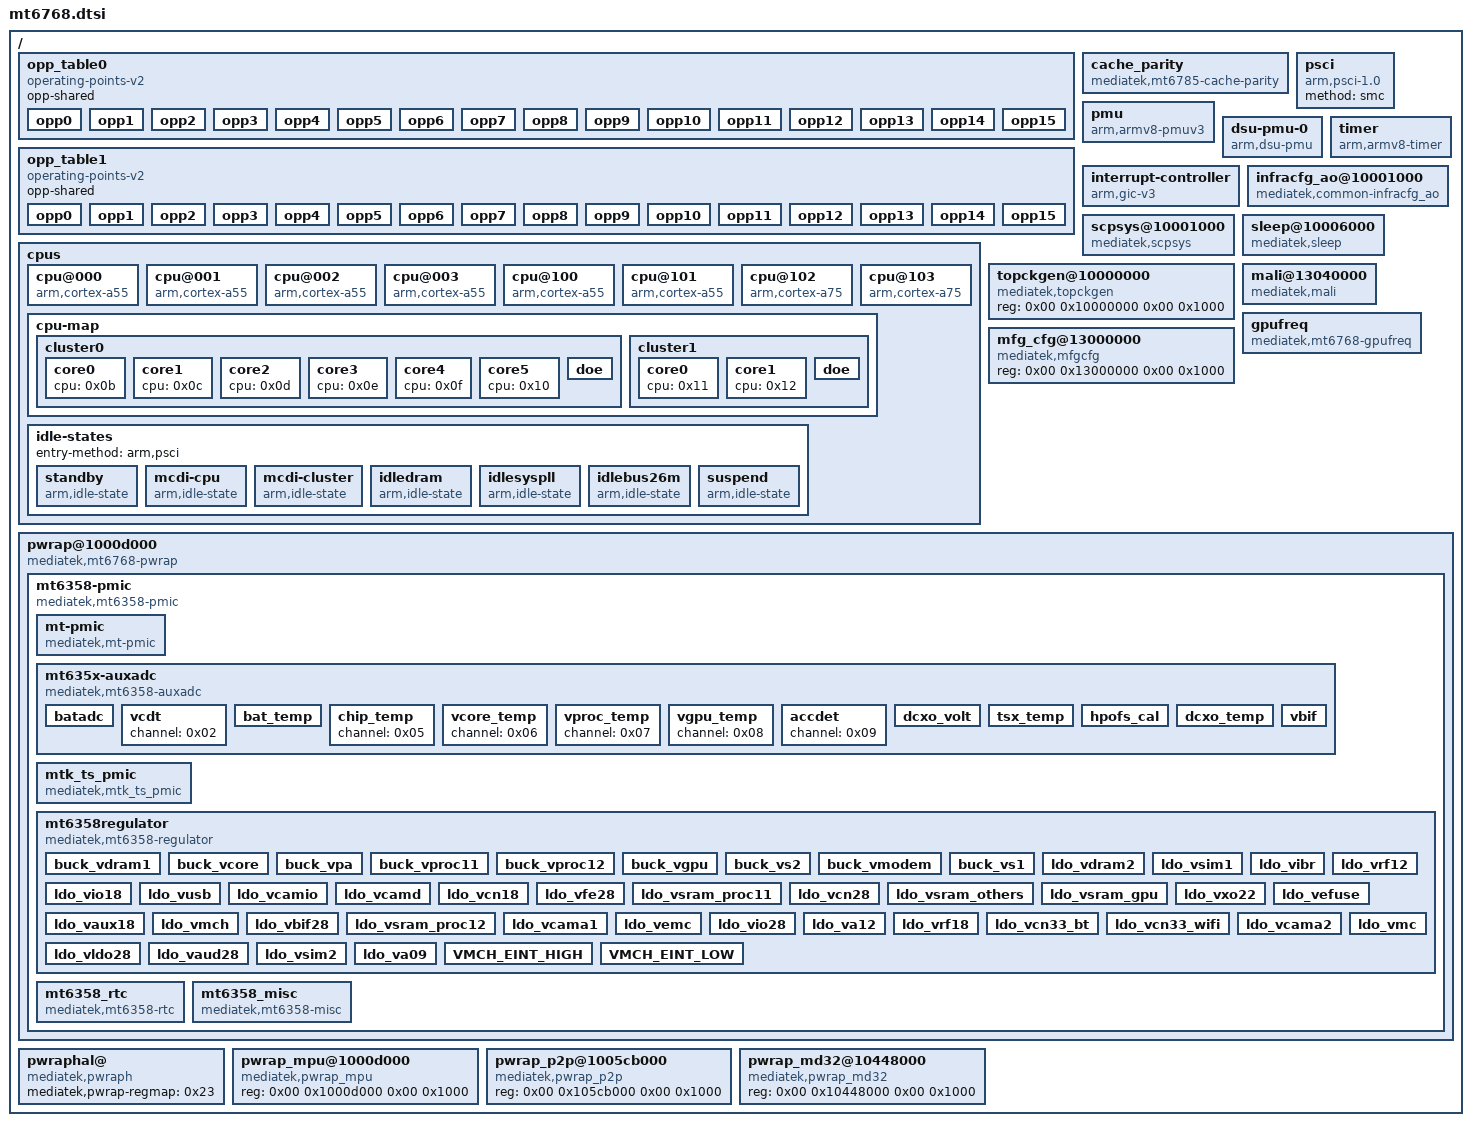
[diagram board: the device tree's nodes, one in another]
// SPDX-License-Identifier: GPL-2.0-only
// Shared MediaTek MT6768/MT6769Z resources.
/ {

	opp_table0 {
		compatible = "operating-points-v2";
		opp-shared;
		phandle = <0x02>;

		opp0 {
			opp-hz = <0x00 0x1dcd6500>;
			opp-microvolt = <0x9eb10>;
		};

		opp1 {
			opp-hz = <0x00 0x2e224d80>;
			opp-microvolt = <0xa4cb8>;
		};

		opp2 {
			opp-hz = <0x00 0x32a9f880>;
			opp-microvolt = <0xaae60>;
		};

		opp3 {
			opp-hz = <0x00 0x35a4e900>;
			opp-microvolt = <0xaf79e>;
		};

		opp4 {
			opp-hz = <0x00 0x389fd980>;
			opp-microvolt = <0xb2872>;
		};

		opp5 {
			opp-hz = <0x00 0x3b8b87c0>;
			opp-microvolt = <0xb5946>;
		};

		opp6 {
			opp-hz = <0x00 0x3e95ba80>;
			opp-microvolt = <0xba284>;
		};

		opp7 {
			opp-hz = <0x00 0x4190ab00>;
			opp-microvolt = <0xbd358>;
		};

		opp8 {
			opp-hz = <0x00 0x460913c0>;
			opp-microvolt = "\0\f5";
		};

		opp9 {
			opp-hz = <0x00 0x4bfef4c0>;
			opp-microvolt = <0xcaf12>;
		};

		opp10 {
			opp-hz = <0x00 0x4ef9e540>;
			opp-microvolt = <0xcdfe6>;
		};

		opp11 {
			opp-hz = <0x00 0x51f4d5c0>;
			opp-microvolt = <0xd10ba>;
		};

		opp12 {
			opp-hz = <0x00 0x566d3e80>;
			opp-microvolt = <0xd7262>;
		};

		opp13 {
			opp-hz = <0x00 0x59682f00>;
			opp-microvolt = <0xda336>;
		};

		opp14 {
			opp-hz = <0x00 0x60db8840>;
			opp-microvolt = <0xe35b2>;
		};

		opp15 {
			opp-hz = <0x00 0x6553f100>;
			opp-microvolt = <0xeafc4>;
		};
	};

	opp_table1 {
		compatible = "operating-points-v2";
		opp-shared;
		phandle = <0x0a>;

		opp0 {
			opp-hz = <0x00 0x32a9f880>;
			opp-microvolt = <0xa4cb8>;
		};

		opp1 {
			opp-hz = <0x00 0x362e3d40>;
			opp-microvolt = <0xaae60>;
		};

		opp2 {
			opp-hz = <0x00 0x3b7c4580>;
			opp-microvolt = <0xb2872>;
		};

		opp3 {
			opp-hz = <0x00 0x40ca4dc0>;
			opp-microvolt = <0xbbaee>;
		};

		opp4 {
			opp-hz = <0x00 0x46185600>;
			opp-microvolt = "\0\f5";
		};

		opp5 {
			opp-hz = <0x00 0x4d3021c0>;
			opp-microvolt = <0xcdfe6>;
		};

		opp6 {
			opp-hz = <0x00 0x50b46680>;
			opp-microvolt = <0xd418e>;
		};

		opp7 {
			opp-hz = <0x00 0x56026ec0>;
			opp-microvolt = <0xdbba0>;
		};

		opp8 {
			opp-hz = <0x00 0x5b507700>;
			opp-microvolt = <0xe35b2>;
		};

		opp9 {
			opp-hz = <0x00 0x609e7f40>;
			opp-microvolt = <0xec82e>;
		};

		opp10 {
			opp-hz = <0x00 0x65ec8780>;
			opp-microvolt = <0xf4240>;
		};

		opp11 {
			opp-hz = <0x00 0x6b49d200>;
			opp-microvolt = <0xfbc52>;
		};

		opp12 {
			opp-hz = <0x00 0x6e44c280>;
			opp-microvolt = <0x100590>;
		};

		opp13 {
			opp-hz = <0x00 0x713fb300>;
			opp-microvolt = <0x103664>;
		};

		opp14 {
			opp-hz = <0x00 0x743aa380>;
			opp-microvolt = <0x106738>;
		};

		opp15 {
			opp-hz = <0x00 0x77359400>;
			opp-microvolt = <0x10980c>;
		};
	};

	cpus {
		#address-cells = <0x01>;
		#size-cells = <0x00>;

		cpu@000 {
			device_type = "cpu";
			compatible = "arm,cortex-a55";
			reg = <0x00>;
			enable-method = "psci";
			clock-frequency = <0x65633340>;
			operating-points-v2 = <0x02>;
			dynamic-power-coefficient = <0x55>;
			capacity-dmips-mhz = <0x1ef>;
			cpu-idle-states = <0x03 0x04 0x05 0x06 0x07 0x08 0x09>;
			phandle = <0x0b>;
		};

		cpu@001 {
			device_type = "cpu";
			compatible = "arm,cortex-a55";
			reg = <0x100>;
			enable-method = "psci";
			clock-frequency = <0x65633340>;
			operating-points-v2 = <0x02>;
			dynamic-power-coefficient = <0x55>;
			capacity-dmips-mhz = <0x1ef>;
			cpu-idle-states = <0x03 0x04 0x05 0x06 0x07 0x08 0x09>;
			phandle = <0x0c>;
		};

		cpu@002 {
			device_type = "cpu";
			compatible = "arm,cortex-a55";
			reg = <0x200>;
			enable-method = "psci";
			clock-frequency = <0x65633340>;
			operating-points-v2 = <0x02>;
			dynamic-power-coefficient = <0x55>;
			capacity-dmips-mhz = <0x1ef>;
			cpu-idle-states = <0x03 0x04 0x05 0x06 0x07 0x08 0x09>;
			phandle = <0x0d>;
		};

		cpu@003 {
			device_type = "cpu";
			compatible = "arm,cortex-a55";
			reg = <0x300>;
			enable-method = "psci";
			clock-frequency = <0x65633340>;
			operating-points-v2 = <0x02>;
			dynamic-power-coefficient = <0x55>;
			capacity-dmips-mhz = <0x1ef>;
			cpu-idle-states = <0x03 0x04 0x05 0x06 0x07 0x08 0x09>;
			phandle = <0x0e>;
		};

		cpu@100 {
			device_type = "cpu";
			compatible = "arm,cortex-a55";
			reg = <0x400>;
			enable-method = "psci";
			clock-frequency = <0x65633340>;
			operating-points-v2 = <0x02>;
			dynamic-power-coefficient = <0x55>;
			capacity-dmips-mhz = <0x1ef>;
			cpu-idle-states = <0x03 0x04 0x05 0x06 0x07 0x08 0x09>;
			phandle = <0x0f>;
		};

		cpu@101 {
			device_type = "cpu";
			compatible = "arm,cortex-a55";
			reg = <0x500>;
			enable-method = "psci";
			clock-frequency = <0x65633340>;
			operating-points-v2 = <0x02>;
			dynamic-power-coefficient = <0x55>;
			capacity-dmips-mhz = <0x1ef>;
			cpu-idle-states = <0x03 0x04 0x05 0x06 0x07 0x08 0x09>;
			phandle = <0x10>;
		};

		cpu@102 {
			device_type = "cpu";
			compatible = "arm,cortex-a75";
			reg = <0x600>;
			enable-method = "psci";
			clock-frequency = <0x8166d4c0>;
			operating-points-v2 = <0x0a>;
			dynamic-power-coefficient = <0x113>;
			capacity-dmips-mhz = <0x400>;
			cpu-idle-states = <0x03 0x04 0x05 0x06 0x07 0x08 0x09>;
			phandle = <0x11>;
		};

		cpu@103 {
			device_type = "cpu";
			compatible = "arm,cortex-a75";
			reg = <0x700>;
			enable-method = "psci";
			clock-frequency = <0x8166d4c0>;
			operating-points-v2 = <0x0a>;
			dynamic-power-coefficient = <0x113>;
			capacity-dmips-mhz = <0x400>;
			cpu-idle-states = <0x03 0x04 0x05 0x06 0x07 0x08 0x09>;
			phandle = <0x12>;
		};

		cpu-map {

			cluster0 {

				core0 {
					cpu = <0x0b>;
				};

				core1 {
					cpu = <0x0c>;
				};

				core2 {
					cpu = <0x0d>;
				};

				core3 {
					cpu = <0x0e>;
				};

				core4 {
					cpu = <0x0f>;
				};

				core5 {
					cpu = <0x10>;
				};

				doe {
					phandle = <0x74>;
				};
			};

			cluster1 {

				core0 {
					cpu = <0x11>;
				};

				core1 {
					cpu = <0x12>;
				};

				doe {
					phandle = <0x75>;
				};
			};
		};

		idle-states {
			entry-method = "arm,psci";

			standby {
				compatible = "arm,idle-state";
				arm,psci-suspend-param = <0x01>;
				entry-latency-us = <0x258>;
				exit-latency-us = <0x258>;
				min-residency-us = <0x4b0>;
				phandle = <0x03>;
			};

			mcdi-cpu {
				compatible = "arm,idle-state";
				arm,psci-suspend-param = <0x10001>;
				entry-latency-us = <0x258>;
				exit-latency-us = <0x258>;
				min-residency-us = <0x4b0>;
				phandle = <0x04>;
			};

			mcdi-cluster {
				compatible = "arm,idle-state";
				arm,psci-suspend-param = <0x1010001>;
				entry-latency-us = <0x258>;
				exit-latency-us = <0x258>;
				min-residency-us = <0x4b0>;
				phandle = <0x05>;
			};

			idledram {
				compatible = "arm,idle-state";
				arm,psci-suspend-param = <0x1010002>;
				entry-latency-us = <0x320>;
				exit-latency-us = <0x3e8>;
				min-residency-us = <0x7d0>;
				status = "okay";
				phandle = <0x06>;
			};

			idlesyspll {
				compatible = "arm,idle-state";
				arm,psci-suspend-param = <0x1010003>;
				entry-latency-us = <0x320>;
				exit-latency-us = <0x3e8>;
				min-residency-us = <0x7d0>;
				status = "okay";
				phandle = <0x07>;
			};

			idlebus26m {
				compatible = "arm,idle-state";
				arm,psci-suspend-param = <0x1010004>;
				entry-latency-us = <0x320>;
				exit-latency-us = <0x3e8>;
				min-residency-us = <0x7d0>;
				status = "okay";
				phandle = <0x08>;
			};

			suspend {
				compatible = "arm,idle-state";
				arm,psci-suspend-param = <0x1010005>;
				entry-latency-us = <0x320>;
				exit-latency-us = <0x3e8>;
				min-residency-us = <0x7d0>;
				phandle = <0x09>;
			};
		};
	};

	cache_parity {
		compatible = "mediatek,mt6785-cache-parity";
		reg = <0x00 0xc530000 0x00 0x10000>;
		irq_config = <0x00 0x8090 0xff00 0x8090 0x44 0x8090 0xff 0x01 0x8090 0xff00 0x8090 0x44 0x8090 0xff 0x02 0x8090 0xff00 0x8090 0x44 0x8090 0xff 0x03 0x8090 0xff00 0x8090 0x44 0x8090 0xff 0x04 0x8090 0xff00 0x8090 0x44 0x8090 0xff 0x05 0x8090 0xff00 0x8090 0x44 0x8090 0xff 0x06 0x8090 0xff00 0x8090 0x44 0x8090 0xff 0x07 0x8090 0xff00 0x8090 0x44 0x8090 0xff 0x400 0xc8c0 0x1000000 0xc8c0 0x0c 0xc8c8 0x01>;
		interrupts = <0x00 0x16 0x04 0x00 0x17 0x04 0x00 0x18 0x04 0x00 0x19 0x04 0x00 0x1a 0x04 0x00 0x1b 0x04 0x00 0x1c 0x04 0x00 0x1d 0x04 0x00 0x13 0x04>;
	};

	psci {
		compatible = "arm,psci-1.0";
		method = "smc";
	};

	pmu {
		compatible = "arm,armv8-pmuv3";
		interrupt-parent = <0x13>;
		interrupts = <0x01 0x07 0x08>;
	};

	dsu-pmu-0 {
		compatible = "arm,dsu-pmu";
		interrupts = <0x00 0x12 0x04>;
		cpus = <0x0b 0x0c 0x0d 0x0e 0x0f 0x10 0x11 0x12>;
	};

	interrupt-controller {
		compatible = "arm,gic-v3";
		#interrupt-cells = <0x03>;
		#address-cells = <0x02>;
		#size-cells = <0x02>;
		#redistributor-regions = <0x01>;
		interrupt-parent = <0x13>;
		interrupt-controller;
		reg = <0x00 0xc000000 0x00 0x40000 0x00 0xc040000 0x00 0x200000 0x00 0xc53a650 0x00 0x50>;
		interrupts = <0x01 0x09 0x04>;
		phandle = <0x13>;
	};

	timer {
		compatible = "arm,armv8-timer";
		interrupt-parent = <0x13>;
		interrupts = <0x01 0x0d 0x08 0x01 0x0e 0x08 0x01 0x0b 0x08 0x01 0x0a 0x08>;
		clock-frequency = <0xc65d40>;
		phandle = <0x78>;
	};

	infracfg_ao@10001000 {
		compatible = "mediatek,common-infracfg_ao\0mediatek,infracfg_ao\0syscon";
		reg = <0x00 0x10001000 0x00 0x1000>;
		interrupts = <0x00 0x47 0x01>;
		#clock-cells = <0x01>;
		phandle = <0x26>;
	};

	scpsys@10001000 {
		compatible = "mediatek,scpsys\0syscon";
		reg = <0x00 0x10001000 0x00 0x1000 0x00 0x10006000 0x00 0x1000 0x00 0x14002000 0x00 0x1000 0x00 0x1020e000 0x00 0x1000 0x00 0x18004000 0x00 0x1000 0x00 0x18002000 0x00 0x1000 0x00 0x10000000 0x00 0x1000 0x00 0x16000000 0x00 0x1000 0x00 0x16025000 0x00 0x1000>;
		#clock-cells = <0x01>;
		phandle = <0x27>;
	};

	topckgen@10000000 {
		compatible = "mediatek,topckgen\0syscon";
		reg = <0x00 0x10000000 0x00 0x1000>;
		#clock-cells = <0x01>;
		phandle = <0x14>;
	};

	sleep@10006000 {
		spmfw_version = "pcm_allinone_lp4_term_3200_v1p11\0pcm_allinone_lp4_3600_v1p11\0pcm_allinone_lp4_3200_v1p11\0pcm_allinone_lp3_1866_v1p11";
		compatible = "mediatek,sleep";
		reg = <0x00 0x10006000 0x00 0x1000>;
		interrupts = <0x00 0xc3 0x08>;
		phandle = <0x7d>;
	};

	mfg_cfg@13000000 {
		compatible = "mediatek,mfgcfg\0syscon";
		reg = <0x00 0x13000000 0x00 0x1000>;
		#clock-cells = <0x01>;
		phandle = <0x60>;
	};

	mali@13040000 {
		compatible = "mediatek,mali\0arm,mali-valhall";
		reg = <0x00 0x13040000 0x00 0x4000>;
		interrupts = <0x00 0x112 0x08 0x00 0x113 0x08 0x00 0x114 0x08 0x00 0x115 0x08 0x00 0x116 0x08>;
		interrupt-names = "GPU\0MMU\0JOB\0EVENT\0PWR";
		ged-supply = <0x5f>;
	};

	gpufreq {
		compatible = "mediatek,mt6768-gpufreq";
		clocks = <0x14 0x54 0x14 0x26 0x14 0x06 0x60 0x00 0x27 0x09 0x27 0x04 0x27 0x07 0x27 0x08>;
		clock-names = "clk_mux\0clk_main_parent\0clk_sub_parent\0subsys_mfg_cg\0mtcmos_mfg_async\0mtcmos_mfg\0mtcmos_mfg_core0\0mtcmos_mfg_core1";
		nvmem-cells = <0x61>;
		nvmem-cell-names = "efuse_segment_cell";
		phandle = <0x62>;
	};

	pwrap@1000d000 {
		compatible = "mediatek,mt6768-pwrap";
		reg = <0x00 0x1000d000 0x00 0x1000>;
		reg-names = "pwrap";
		interrupts = <0x00 0xc2 0x04>;
		clocks = <0x15 0x15>;
		clock-names = "spi\0wrap";
		phandle = <0x23>;

		mt6358-pmic {
			compatible = "mediatek,mt6358-pmic";
			interrupt-parent = <0x20>;
			interrupts = <0x90 0x04 0xb4 0x00>;
			status = "okay";
			interrupt-controller;
			#interrupt-cells = <0x02>;
			mediatek,num-pmic-irqs = <0x91>;
			mediatek,pmic-irqs = <0x00 0x00 0x01 0x00 0x02 0x00 0x03 0x00 0x04 0x00 0x05 0x00 0x06 0x00 0x07 0x00 0x08 0x00 0x09 0x00 0x10 0x01 0x11 0x01 0x12 0x01 0x13 0x01 0x14 0x01 0x15 0x01 0x16 0x01 0x17 0x01 0x18 0x01 0x19 0x01 0x1a 0x01 0x1b 0x01 0x1c 0x01 0x1d 0x01 0x1e 0x01 0x1f 0x01 0x20 0x01 0x21 0x01 0x22 0x01 0x23 0x01 0x24 0x01 0x25 0x01 0x26 0x01 0x27 0x01 0x28 0x01 0x29 0x01 0x2a 0x01 0x2b 0x01 0x2c 0x01 0x2d 0x01 0x2e 0x01 0x30 0x02 0x31 0x02 0x32 0x02 0x33 0x02 0x34 0x02 0x35 0x02 0x36 0x02 0x37 0x02 0x40 0x03 0x50 0x04 0x51 0x04 0x52 0x04 0x53 0x04 0x54 0x04 0x55 0x04 0x56 0x04 0x57 0x04 0x58 0x04 0x59 0x04 0x5a 0x04 0x5b 0x04 0x5c 0x04 0x60 0x04 0x61 0x04 0x62 0x04 0x63 0x04 0x64 0x04 0x70 0x05 0x71 0x05 0x72 0x05 0x73 0x05 0x74 0x05 0x75 0x05 0x76 0x05 0x77 0x05 0x80 0x06 0x85 0x06 0x86 0x06 0x87 0x06 0x90 0x07>;
			interrupt-names = "vproc11_oc\0vproc12_oc\0vcore_oc\0vgpu_oc\0vmodem_oc\0vdram1_oc\0vs1_oc\0vs2_oc\0vpa_oc\0vcore_preoc\0vfe28_oc\0vxo22_oc\0vrf18_oc\0vrf12_oc\0vefuse_oc\0vcn33_oc\0vcn28_oc\0vcn18_oc\0vcama1_oc\0vcama2_oc\0vcamd_oc\0vcamio_oc\0vldo28_oc\0va12_oc\0vaux18_oc\0vaud28_oc\0vio28_oc\0vio18_oc\0vsram_proc11_oc\0vsram_proc12_oc\0vsram_others_oc\0vsram_gpu_oc\0vdram2_oc\0vmc_oc\0vmch_oc\0vemc_oc\0vsim1_oc\0vsim2_oc\0vibr_oc\0vusb_oc\0vbif28_oc\0pwrkey\0homekey\0pwrkey_r\0homekey_r\0ni_lbat_int\0chrdet\0chrdet_edge\0vcdt_hv_det\0rtc\0fg_bat0_h\0fg_bat0_l\0fg_cur_h\0fg_cur_l\0fg_zcv\0fg_bat1_h\0fg_bat1_l\0fg_n_charge_l\0fg_iavg_h\0fg_iavg_l\0fg_time_h\0fg_discharge\0fg_charge\0baton_lv\0baton_ht\0baton_bat_in\0baton_bat_out\0bif\0bat_h\0bat_l\0bat2_h\0bat2_l\0bat_temp_h\0bat_temp_l\0auxadc_imp\0nag_c_dltv\0audio\0accdet\0accdet_eint0\0accdet_eint1\0spi_cmd_alert";
			phandle = <0x81>;

			mt-pmic {
				compatible = "mediatek,mt-pmic";
				interrupts = <0x30 0x04 0x32 0x04 0x31 0x04 0x33 0x04 0x70 0x04 0x71 0x04 0x52 0x04 0x53 0x04 0x36 0x03>;
				interrupt-names = "pwrkey\0pwrkey_r\0homekey\0homekey_r\0bat_h\0bat_l\0fg_cur_h\0fg_cur_l\0chrdet_edge";
				phandle = <0x82>;
			};

			mt635x-auxadc {
				compatible = "mediatek,mt6358-auxadc";
				#io-channel-cells = <0x01>;
				phandle = <0x21>;

				batadc {
					channel = <0x00>;
					resistance-ratio = <0x03 0x01>;
					avg-num = <0x80>;
				};

				vcdt {
					channel = <0x02>;
				};

				bat_temp {
					channel = <0x03>;
					resistance-ratio = <0x02 0x01>;
				};

				chip_temp {
					channel = <0x05>;
				};

				vcore_temp {
					channel = <0x06>;
				};

				vproc_temp {
					channel = <0x07>;
				};

				vgpu_temp {
					channel = <0x08>;
				};

				accdet {
					channel = <0x09>;
				};

				dcxo_volt {
					channel = <0x0a>;
					resistance-ratio = <0x03 0x02>;
				};

				tsx_temp {
					channel = <0x0b>;
					avg-num = <0x80>;
				};

				hpofs_cal {
					channel = <0x0c>;
					avg-num = <0x100>;
				};

				dcxo_temp {
					channel = <0x0d>;
					avg-num = <0x10>;
				};

				vbif {
					channel = <0x0e>;
					resistance-ratio = <0x02 0x01>;
				};
			};

			mtk_ts_pmic {
				compatible = "mediatek,mtk_ts_pmic";
				io-channels = <0x21 0x05 0x21 0x06 0x21 0x07>;
				io-channel-names = "pmic_chip_temp\0pmic_buck1_temp\0pmic_buck2_temp";
				interconnects = <0x21 0x01>;
				#interconnect-cells = <0x01>;
				phandle = <0x83>;
			};

			mt6358regulator {
				compatible = "mediatek,mt6358-regulator";
				phandle = <0x84>;

				buck_vdram1 {
					regulator-name = "vdram1";
					regulator-min-microvolt = <0x7a120>;
					regulator-max-microvolt = <0x1fda4c>;
					regulator-enable-ramp-delay = <0x00>;
					phandle = <0x85>;
				};

				buck_vcore {
					regulator-name = "vcore";
					regulator-min-microvolt = <0x7a120>;
					regulator-max-microvolt = <0x13bdb6>;
					regulator-enable-ramp-delay = <0xc8>;
					phandle = <0x29>;
				};

				buck_vpa {
					regulator-name = "vpa";
					regulator-min-microvolt = <0x7a120>;
					regulator-max-microvolt = <0x37b1d0>;
					regulator-enable-ramp-delay = <0xfa>;
					phandle = <0x86>;
				};

				buck_vproc11 {
					regulator-name = "vproc11";
					regulator-min-microvolt = <0x7a120>;
					regulator-max-microvolt = <0x13bdb6>;
					regulator-enable-ramp-delay = <0xc8>;
					phandle = <0x87>;
				};

				buck_vproc12 {
					regulator-name = "vproc12";
					regulator-min-microvolt = <0x7a120>;
					regulator-max-microvolt = <0x13bdb6>;
					regulator-enable-ramp-delay = <0xc8>;
					phandle = <0x88>;
				};

				buck_vgpu {
					regulator-name = "vgpu";
					regulator-min-microvolt = <0x7a120>;
					regulator-max-microvolt = <0x13bdb6>;
					regulator-enable-ramp-delay = <0xc8>;
					phandle = <0x89>;
				};

				buck_vs2 {
					regulator-name = "vs2";
					regulator-min-microvolt = <0x7a120>;
					regulator-max-microvolt = <0x1fda4c>;
					regulator-enable-ramp-delay = <0x00>;
					phandle = <0x8a>;
				};

				buck_vmodem {
					regulator-name = "vmodem";
					regulator-min-microvolt = <0x7a120>;
					regulator-max-microvolt = <0x13bdb6>;
					regulator-enable-ramp-delay = <0x384>;
					phandle = <0x28>;
				};

				buck_vs1 {
					regulator-name = "vs1";
					regulator-min-microvolt = <0xf4240>;
					regulator-max-microvolt = <0x277b6c>;
					regulator-enable-ramp-delay = <0x00>;
					phandle = <0x8b>;
				};

				ldo_vdram2 {
					regulator-name = "vdram2";
					regulator-min-microvolt = <0x927c0>;
					regulator-max-microvolt = <0x1b7740>;
					regulator-enable-ramp-delay = <0xce4>;
					phandle = <0x8c>;
				};

				ldo_vsim1 {
					regulator-name = "vsim1";
					regulator-min-microvolt = <0x19f0a0>;
					regulator-max-microvolt = <0x2f4d60>;
					regulator-enable-ramp-delay = <0x21c>;
					phandle = <0x8d>;
					regulator-default-on = <0x01>;
					status = "okay";
				};

				ldo_vibr {
					regulator-name = "vibr";
					regulator-min-microvolt = <0x124f80>;
					regulator-max-microvolt = <0x325aa0>;
					regulator-enable-ramp-delay = <0x3c>;
					phandle = <0x8e>;
				};

				ldo_vrf12 {
					regulator-name = "vrf12";
					regulator-min-microvolt = <0x124f80>;
					regulator-max-microvolt = <0x124f80>;
					regulator-enable-ramp-delay = <0x78>;
					phandle = <0x8f>;
				};

				ldo_vio18 {
					regulator-name = "vio18";
					regulator-min-microvolt = <0x1b7740>;
					regulator-max-microvolt = <0x1b7740>;
					regulator-enable-ramp-delay = <0xa8c>;
					regulator-always-on;
					phandle = <0x90>;
				};

				ldo_vusb {
					regulator-name = "vusb";
					regulator-min-microvolt = <0x2dc6c0>;
					regulator-max-microvolt = <0x2f4d60>;
					regulator-enable-ramp-delay = <0x10e>;
					phandle = <0x91>;
				};

				ldo_vcamio {
					regulator-name = "vcamio";
					regulator-min-microvolt = <0x1b7740>;
					regulator-max-microvolt = <0x1b7740>;
					regulator-enable-ramp-delay = <0x10e>;
					phandle = <0x92>;
					regulator-default-on = <0x01>;
					status = "okay";
				};

				ldo_vcamd {
					regulator-name = "vcamd";
					regulator-min-microvolt = <0xdbba0>;
					regulator-max-microvolt = <0x1b7740>;
					regulator-enable-ramp-delay = <0x10e>;
					phandle = <0x93>;
					regulator-default-on = <0x01>;
					status = "okay";
				};

				ldo_vcn18 {
					regulator-name = "vcn18";
					regulator-min-microvolt = <0x1b7740>;
					regulator-max-microvolt = <0x1b7740>;
					regulator-enable-ramp-delay = <0x10e>;
					phandle = <0x94>;
				};

				ldo_vfe28 {
					regulator-name = "vfe28";
					regulator-min-microvolt = <0x2ab980>;
					regulator-max-microvolt = <0x2ab980>;
					regulator-enable-ramp-delay = <0x10e>;
					phandle = <0x95>;
				};

				ldo_vsram_proc11 {
					regulator-name = "vsram_proc11";
					regulator-min-microvolt = <0x7a120>;
					regulator-max-microvolt = <0x13bdb6>;
					regulator-enable-ramp-delay = <0xf0>;
					phandle = <0x96>;
				};

				ldo_vcn28 {
					regulator-name = "vcn28";
					regulator-min-microvolt = <0x2ab980>;
					regulator-max-microvolt = <0x2ab980>;
					regulator-enable-ramp-delay = <0x10e>;
					phandle = <0x97>;
				};

				ldo_vsram_others {
					regulator-name = "vsram_others";
					regulator-min-microvolt = <0x7a120>;
					regulator-max-microvolt = <0x13bdb6>;
					regulator-enable-ramp-delay = <0xf0>;
					phandle = <0x98>;
				};

				ldo_vsram_gpu {
					regulator-name = "vsram_gpu";
					regulator-min-microvolt = <0x7a120>;
					regulator-max-microvolt = <0x13bdb6>;
					regulator-enable-ramp-delay = <0xf0>;
					phandle = <0x99>;
				};

				ldo_vxo22 {
					regulator-name = "vxo22";
					regulator-min-microvolt = <0x2191c0>;
					regulator-max-microvolt = <0x2191c0>;
					regulator-enable-ramp-delay = <0x78>;
					phandle = <0x9a>;
				};

				ldo_vefuse {
					regulator-name = "vefuse";
					regulator-min-microvolt = <0x19f0a0>;
					regulator-max-microvolt = <0x1cfde0>;
					regulator-enable-ramp-delay = <0x10e>;
					phandle = <0x9b>;
				};

				ldo_vaux18 {
					regulator-name = "vaux18";
					regulator-min-microvolt = <0x1b7740>;
					regulator-max-microvolt = <0x1b7740>;
					regulator-enable-ramp-delay = <0x10e>;
					phandle = <0x9c>;
				};

				ldo_vmch {
					regulator-name = "vmch";
					regulator-min-microvolt = <0x2c4020>;
					regulator-max-microvolt = <0x325aa0>;
					regulator-enable-ramp-delay = <0x3c>;
					phandle = <0x41>;
				};

				ldo_vbif28 {
					regulator-name = "vbif28";
					regulator-min-microvolt = <0x2ab980>;
					regulator-max-microvolt = <0x2ab980>;
					regulator-enable-ramp-delay = <0x10e>;
					phandle = <0x9d>;
				};

				ldo_vsram_proc12 {
					regulator-name = "vsram_proc12";
					regulator-min-microvolt = <0x7a120>;
					regulator-max-microvolt = <0x13bdb6>;
					regulator-enable-ramp-delay = <0xf0>;
					phandle = <0x9e>;
				};

				ldo_vcama1 {
					regulator-name = "vcama1";
					regulator-min-microvolt = <0x1b7740>;
					regulator-max-microvolt = <0x2dc6c0>;
					regulator-enable-ramp-delay = <0x10e>;
					phandle = <0x9f>;
					regulator-default-on = <0x01>;
					status = "okay";
				};

				ldo_vemc {
					regulator-name = "vemc";
					regulator-min-microvolt = <0x2c4020>;
					regulator-max-microvolt = <0x325aa0>;
					regulator-enable-ramp-delay = <0x3c>;
					phandle = <0x3d>;
				};

				ldo_vio28 {
					regulator-name = "vio28";
					regulator-min-microvolt = <0x2ab980>;
					regulator-max-microvolt = <0x2ab980>;
					regulator-enable-ramp-delay = <0x10e>;
					phandle = <0xa0>;
				};

				ldo_va12 {
					regulator-name = "va12";
					regulator-min-microvolt = <0x124f80>;
					regulator-max-microvolt = <0x124f80>;
					regulator-enable-ramp-delay = <0x10e>;
					phandle = <0xa1>;
				};

				ldo_vrf18 {
					regulator-name = "vrf18";
					regulator-min-microvolt = <0x1b7740>;
					regulator-max-microvolt = <0x1b7740>;
					regulator-enable-ramp-delay = <0x78>;
					phandle = <0xa2>;
				};

				ldo_vcn33_bt {
					regulator-name = "vcn33_bt";
					regulator-min-microvolt = <0x325aa0>;
					regulator-max-microvolt = <0x3567e0>;
					regulator-enable-ramp-delay = <0x10e>;
					phandle = <0xa3>;
				};

				ldo_vcn33_wifi {
					regulator-name = "vcn33_wifi";
					regulator-min-microvolt = <0x325aa0>;
					regulator-max-microvolt = <0x3567e0>;
					regulator-enable-ramp-delay = <0x10e>;
					phandle = <0xa4>;
				};

				ldo_vcama2 {
					regulator-name = "vcama2";
					regulator-min-microvolt = <0x1b7740>;
					regulator-max-microvolt = <0x2dc6c0>;
					regulator-enable-ramp-delay = <0x10e>;
					phandle = <0xa5>;
					regulator-default-on = <0x01>;
					status = "okay";
				};

				ldo_vmc {
					regulator-name = "vmc";
					regulator-min-microvolt = <0x1b7740>;
					regulator-max-microvolt = <0x325aa0>;
					regulator-enable-ramp-delay = <0x3c>;
					phandle = <0x42>;
				};

				ldo_vldo28 {
					regulator-name = "vldo28";
					regulator-min-microvolt = <0x2ab980>;
					regulator-max-microvolt = <0x2ab980>;
					regulator-enable-ramp-delay = <0x10e>;
					phandle = <0xa6>;
					regulator-default-on = <0x01>;
					status = "okay";
				};

				ldo_vaud28 {
					regulator-name = "vaud28";
					regulator-min-microvolt = <0x2ab980>;
					regulator-max-microvolt = <0x2ab980>;
					regulator-enable-ramp-delay = <0x10e>;
					phandle = <0xa7>;
				};

				ldo_vsim2 {
					regulator-name = "vsim2";
					regulator-min-microvolt = <0x19f0a0>;
					regulator-max-microvolt = <0x2f4d60>;
					regulator-enable-ramp-delay = <0x21c>;
					phandle = <0xa8>;
					regulator-default-on = <0x01>;
					status = "okay";
				};

				ldo_va09 {
					regulator-name = "va09";
					regulator-min-microvolt = <0xdbba0>;
					regulator-max-microvolt = <0xdbba0>;
					regulator-enable-ramp-delay = <0x108>;
					regulator-boot-on;
					phandle = <0xa9>;
				};

				VMCH_EINT_HIGH {
					regulator-name = "mt6358_vmch_eint_high";
					regulator-min-microvolt = <0x2c4020>;
					regulator-max-microvolt = <0x325aa0>;
					regulator-enable-ramp-delay = <0x3c>;
					phandle = <0xaa>;
				};

				VMCH_EINT_LOW {
					regulator-name = "mt6358_vmch_eint_low";
					regulator-min-microvolt = <0x2c4020>;
					regulator-max-microvolt = <0x325aa0>;
					regulator-enable-ramp-delay = <0x3c>;
					phandle = <0xab>;
				};
			};

			mt6358_rtc {
				compatible = "mediatek,mt6358-rtc";
				bootmode = <0x22>;
				interrupts = <0x40 0x00>;
				interrupt-names = "rtc";
				base = <0x580>;
				apply-lpsd-solution;
				phandle = <0xac>;
			};

			mt6358_misc {
				compatible = "mediatek,mt6358-misc";
				base = <0x580>;
				apply-lpsd-solution;
				dcxo-switch;
				phandle = <0xad>;
			};
		};
	};

	pwraphal@ {
		compatible = "mediatek,pwraph";
		mediatek,pwrap-regmap = <0x23>;
		phandle = <0xae>;
	};

	pwrap_mpu@1000d000 {
		compatible = "mediatek,pwrap_mpu";
		reg = <0x00 0x1000d000 0x00 0x1000>;
	};

	pwrap_p2p@1005cb000 {
		compatible = "mediatek,pwrap_p2p";
		reg = <0x00 0x105cb000 0x00 0x1000>;
	};

	pwrap_md32@10448000 {
		compatible = "mediatek,pwrap_md32";
		reg = <0x00 0x10448000 0x00 0x1000>;
	};

};

